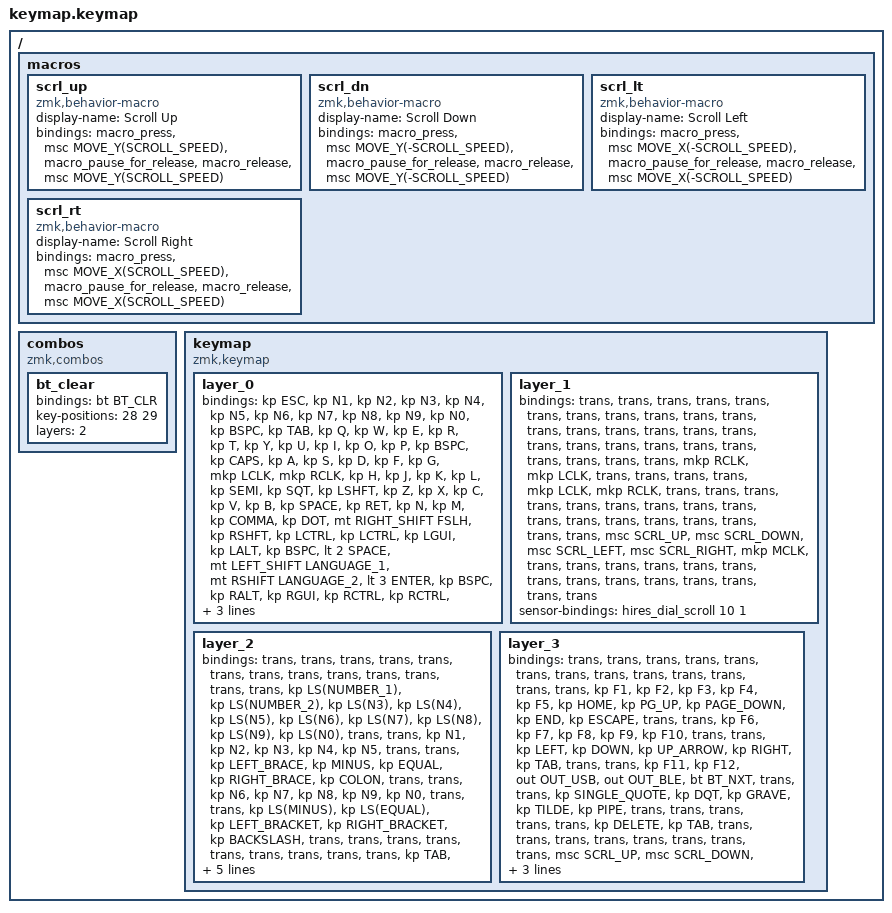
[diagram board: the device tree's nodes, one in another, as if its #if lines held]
#include <behaviors.dtsi>
#include <dt-bindings/zmk/bt.h>
#include <dt-bindings/zmk/keys.h>
#include <dt-bindings/zmk/outputs.h>
#include <dt-bindings/zmk/pointing.h>

#if defined(TORABO_TSUKI_LP_INPUT_HIRES_DIAL)
#include <behaviors/hires_dial.dtsi>
#endif

/*
 * Scroll speed for the Studio-selectable Scroll Up/Down/Left/Right macros,
 * in wheel notches per second while the key is held. macOS ignores HID
 * high-resolution scrolling, so one notch is the smallest step; keep this
 * low so holding the key scrolls gradually and a short tap moves one notch.
 */
#define SCROLL_SPEED 4

/ {
    macros {
        scrl_up: scrl_up {
            compatible = "zmk,behavior-macro";
            #binding-cells = <0>;
            display-name = "Scroll Up";
            bindings = <&macro_press &msc MOVE_Y(SCROLL_SPEED)>, <&macro_pause_for_release>, <&macro_release &msc MOVE_Y(SCROLL_SPEED)>;
        };
        scrl_dn: scrl_dn {
            compatible = "zmk,behavior-macro";
            #binding-cells = <0>;
            display-name = "Scroll Down";
            bindings = <&macro_press &msc MOVE_Y(-SCROLL_SPEED)>, <&macro_pause_for_release>, <&macro_release &msc MOVE_Y(-SCROLL_SPEED)>;
        };
        scrl_lt: scrl_lt {
            compatible = "zmk,behavior-macro";
            #binding-cells = <0>;
            display-name = "Scroll Left";
            bindings = <&macro_press &msc MOVE_X(-SCROLL_SPEED)>, <&macro_pause_for_release>, <&macro_release &msc MOVE_X(-SCROLL_SPEED)>;
        };
        scrl_rt: scrl_rt {
            compatible = "zmk,behavior-macro";
            #binding-cells = <0>;
            display-name = "Scroll Right";
            bindings = <&macro_press &msc MOVE_X(SCROLL_SPEED)>, <&macro_pause_for_release>, <&macro_release &msc MOVE_X(SCROLL_SPEED)>;
        };
    };
};

/ {
    combos {
        compatible = "zmk,combos";

        bt_clear {
            bindings = <&bt BT_CLR>;
            key-positions = <28 29>;
            layers = <2>;
        };
    };

    keymap {
        compatible = "zmk,keymap";

        layer_0 {
            bindings = <
&kp ESC    &kp N1     &kp N2    &kp N3    &kp N4    &kp N5                                                         &kp N6       &kp N7    &kp N8     &kp N9    &kp N0                &kp BSPC
&kp TAB    &kp Q      &kp W     &kp E     &kp R     &kp T                                                          &kp Y        &kp U     &kp I      &kp O     &kp P                 &kp BSPC
&kp CAPS   &kp A      &kp S     &kp D     &kp F     &kp G        &mkp LCLK                  &mkp RCLK              &kp H        &kp J     &kp K      &kp L     &kp SEMI              &kp SQT
&kp LSHFT  &kp Z      &kp X     &kp C     &kp V     &kp B        &kp SPACE                  &kp RET                &kp N        &kp M     &kp COMMA  &kp DOT   &mt RIGHT_SHIFT FSLH  &kp RSHFT
&kp LCTRL  &kp LCTRL  &kp LGUI  &kp LALT  &kp BSPC  &lt 2 SPACE  &mt LEFT_SHIFT LANGUAGE_1  &mt RSHIFT LANGUAGE_2  &lt 3 ENTER  &kp BSPC  &kp RALT   &kp RGUI  &kp RCTRL             &kp RCTRL
#if defined(TORABO_TSUKI_LP_KSCAN_4_DIRECTION_SWITCH)
&msc SCRL_UP &msc SCRL_DOWN &msc SCRL_LEFT &msc SCRL_RIGHT &mkp MCLK
#elif defined(TORABO_TSUKI_LP_INPUT_HIRES_DIAL)
&mkp MCLK
#endif
            >;
        };

        layer_1 {
            bindings = <
&trans  &trans  &trans  &trans     &trans     &trans                  &trans  &trans     &trans     &trans  &trans  &trans
&trans  &trans  &trans  &trans     &trans     &trans                  &trans  &trans     &trans     &trans  &trans  &trans
&trans  &trans  &trans  &mkp RCLK  &mkp LCLK  &trans  &trans  &trans  &trans  &mkp LCLK  &mkp RCLK  &trans  &trans  &trans
&trans  &trans  &trans  &trans     &trans     &trans  &trans  &trans  &trans  &trans     &trans     &trans  &trans  &trans
#if defined(TORABO_TSUKI_LP_KSCAN_4_DIRECTION_SWITCH)
&msc SCRL_UP &msc SCRL_DOWN &msc SCRL_LEFT &msc SCRL_RIGHT &mkp MCLK
#elif defined(TORABO_TSUKI_LP_INPUT_HIRES_DIAL)
&mkp MCLK
#endif
&trans  &trans  &trans  &trans     &trans     &trans  &trans  &trans  &trans  &trans     &trans     &trans  &trans  &trans
            >;
        };

        layer_2 {
            bindings = <
&trans  &trans            &trans            &trans      &trans      &trans                      &trans          &trans         &trans            &trans             &trans         &trans
&trans  &kp LS(NUMBER_1)  &kp LS(NUMBER_2)  &kp LS(N3)  &kp LS(N4)  &kp LS(N5)                  &kp LS(N6)      &kp LS(N7)     &kp LS(N8)        &kp LS(N9)         &kp LS(N0)     &trans
&trans  &kp N1            &kp N2            &kp N3      &kp N4      &kp N5      &trans  &trans  &kp LEFT_BRACE  &kp MINUS      &kp EQUAL         &kp RIGHT_BRACE    &kp COLON      &trans
&trans  &kp N6            &kp N7            &kp N8      &kp N9      &kp N0      &trans  &trans  &kp LS(MINUS)   &kp LS(EQUAL)  &kp LEFT_BRACKET  &kp RIGHT_BRACKET  &kp BACKSLASH  &trans
&trans  &trans            &trans            &trans      &trans      &trans      &trans  &trans  &kp TAB         &kp DEL        &trans            &trans             &trans         &trans
#if defined(TORABO_TSUKI_LP_KSCAN_4_DIRECTION_SWITCH)
&msc SCRL_UP &msc SCRL_DOWN &msc SCRL_LEFT &msc SCRL_RIGHT &mkp MCLK
#elif defined(TORABO_TSUKI_LP_INPUT_HIRES_DIAL)
&kp C_MUTE
#endif
            >;
        };

        layer_3 {
            bindings = <
&trans  &trans   &trans   &trans        &trans        &trans                      &trans            &trans     &trans         &trans     &trans      &trans
&trans  &kp F1   &kp F2   &kp F3        &kp F4        &kp F5                      &kp HOME          &kp PG_UP  &kp PAGE_DOWN  &kp END    &kp ESCAPE  &trans
&trans  &kp F6   &kp F7   &kp F8        &kp F9        &kp F10     &trans  &trans  &kp LEFT          &kp DOWN   &kp UP_ARROW   &kp RIGHT  &kp TAB     &trans
&trans  &kp F11  &kp F12  &out OUT_USB  &out OUT_BLE  &bt BT_NXT  &trans  &trans  &kp SINGLE_QUOTE  &kp DQT    &kp GRAVE      &kp TILDE  &kp PIPE    &trans
&trans  &trans   &trans   &trans        &kp DELETE    &kp TAB     &trans  &trans  &trans            &trans     &trans         &trans     &trans      &trans
#if defined(TORABO_TSUKI_LP_KSCAN_4_DIRECTION_SWITCH)
&msc SCRL_UP &msc SCRL_DOWN &msc SCRL_LEFT &msc SCRL_RIGHT &mkp MCLK
#elif defined(TORABO_TSUKI_LP_INPUT_HIRES_DIAL)
&hires_dial_radial_controller_button
#endif
            >;
        };
    };
};

#if defined(TORABO_TSUKI_LP_INPUT_HIRES_DIAL)
&{/keymap/layer_0} {
    sensor-bindings = <&hires_dial_scroll 1 1>;
};

&{/keymap/layer_1} {
    sensor-bindings = <&hires_dial_scroll 10 1>;
};

&{/keymap/layer_2} {
    sensor-bindings = <&hires_dial_encoder C_VOL_UP C_VOL_DN>;
};

&{/keymap/layer_3} {
    /* Quarter-speed Radial Controller motion: output/input = 1/4. */
    sensor-bindings = <&hires_dial_radial_controller 4 1>;
};
#endif
